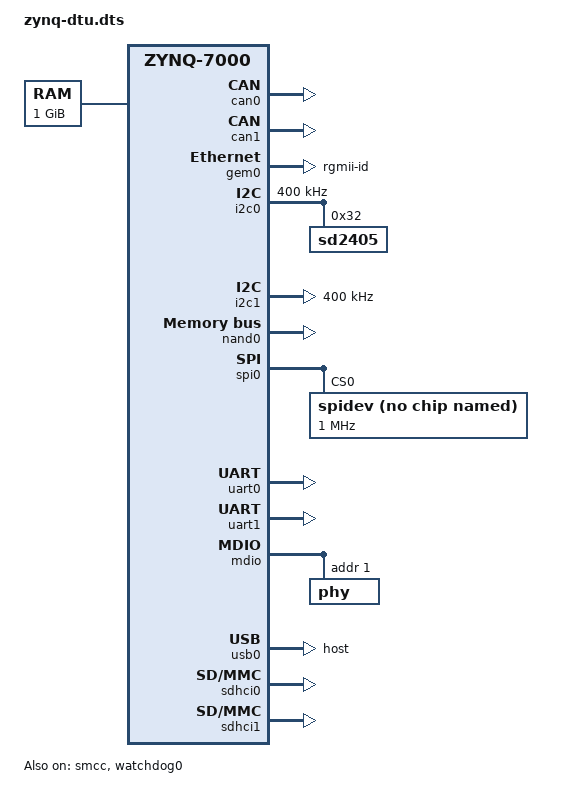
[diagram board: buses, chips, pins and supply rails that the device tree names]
/*
 * CAUTION: This file is automatically generated by Xilinx.
 * Version:  
 * Today is: Tue May 15 16:33:56 2018
*/


/dts-v1/;
/include/ "zynq-7000_jie.dtsi"
/include/ "pl.dtsi"
/ {
	cpus {
		cpu@0 {
			operating-points = <666666 1000000 333333 1000000>;
		};
	};
	chosen {
		bootargs = "console=ttyPS0,115200";
	};
	aliases {
		ethernet0 = &gem0;
		ethernet1 = &gem1;
		serial0 = &uart0;
		serial1 = &uart1;
	/*	serial2 = &axi_uarthzhy_0;
		serial3 = &axi_uarthzhy_1;
		serial4 = &axi_uarthzhy_2;
		serial5 = &axi_uarthzhy_3;*/
		spi0 = &spi0;
	};
	memory {
		device_type = "memory";
		reg = <0x0 0x40000000>;
	};
};
&can0 {
	status = "okay";
};
&can1 {
	status = "okay";
};
&gem0 {
	local-mac-address = [00 0a 35 00 00 00];
	phy-mode = "rgmii-id";
	status = "okay";
	xlnx,ptp-enet-clock = <0x69f6bcb>;
	phy-handle = <0x10>;
};

/*&gem1 {
	local-mac-address = [00 0a 35 00 00 01];
	phy-mode = "rgmii-id";
	status = "okay";
	xlnx,ptp-enet-clock = <0x69f6bcb>;
	phy-handle = <0x11>;
};*/
&gpio0 {
	emio-gpio-width = <5>;
	gpio-mask-high = <0x0>;
	gpio-mask-low = <0x5600>;
	hzhy_gpio {
	    //gpio0_34中断
	    compatible = "hzhy_gpio";
	    hzhy_io = <&gpio0 15 0>,<&gpio0 47 0>,<&gpio0 48 0>,<&gpio0 54 0>,<&gpio0 55 0>,
			      <&gpio0 56 0>,<&gpio0 57 0>,<&gpio0 58 0>,<&gpio0 59 0>,<&gpio0 60 0>;
		};
};
&i2c0 {
	clock-frequency = <400000>;
	status = "okay";
	
	sd2405@32 {
		compatible = "sd2405";
		reg = <0x32>;
				interrupts = <0 36 1>;
	};
};
&i2c1 {
	clock-frequency = <400000>;
	status = "okay";
};
&intc {
	num_cpus = <2>;
	num_interrupts = <96>;
};
&nand0 {
	arm,nand-cycle-t0 = <0x5>;
	arm,nand-cycle-t1 = <0x5>;
	arm,nand-cycle-t2 = <0x2>;
	arm,nand-cycle-t3 = <0x2>;
	arm,nand-cycle-t4 = <0x2>;
	arm,nand-cycle-t5 = <0x1>;
	arm,nand-cycle-t6 = <0x2>;
	status = "okay";
	
	partition@nand-fsbl-uboot {
		label = "nand-fsbl-uboot";
		reg = <0x0 0x600000>;
	};
	partition@nand-linux {
		label = "nand-linux";
		reg = <0x600000 0x400000>;
	};
	partition@nand-device-tree {
		label = "nand-device-tree";
		reg = <0xA00000 0x20000>;
	};
	partition@nand-rootfs {
		label = "nand-rootfs";
		reg = <0xA20000 0x1E5E0000>;
	};
	partition@nand-env {
		label = "nand-env";
		reg = <0x1F000000 0x20000>;
	};
};
&smcc {
	status = "okay";
};
&spi0 {
	is-decoded-cs = <0>;
	num-cs = <3>;
	status = "okay";
	
	spidev@0 {
		compatible = "linux,spidev";
		spi-max-frequency = <1000000>;
		reg = <0x0>;
	};
};
&uart0 {
	device_type = "serial";
	port-number = <0>;
	status = "okay";
};
&uart1 {
	device_type = "serial";
	port-number = <1>;
	status = "okay";
};
&clkc {
	fclk-enable = <0x0>;
	ps-clk-frequency = <33333333>;
};

&mdio {
	status = "okay";
/*	phy@30 {
		device_type = "ethernet-phy";
		reg = <0x1e>;
		linux,phandle = <0x11>;
		phandle = <0x11>;
	};*/
	
	phy@1 {
		device_type = "ethernet-phy";
		reg = <0x01>;
		linux,phandle = <0x10>;
		phandle = <0x10>;
	};		

};
&usb0 {
	status = "okay";
	dr_mode = "host";	 
    compatible = "ulpi-phy";
    #phy-cells = <0>;
    view-port = <0x170>;
    drv-vbus;
};

&sdhci0 {
	status = "okay";
	xlnx,has-cd = <0x1>;
	xlnx,has-power = <0x0>;
	xlnx,has-wp = <0x1>;
};

&sdhci1 {
	status = "okay";
	xlnx,has-cd = <0x1>;
	xlnx,has-power = <0x0>;
	xlnx,has-wp = <0x1>;
};

&watchdog0 {
	    status = "okay";
		reset-on-timeout;
};





